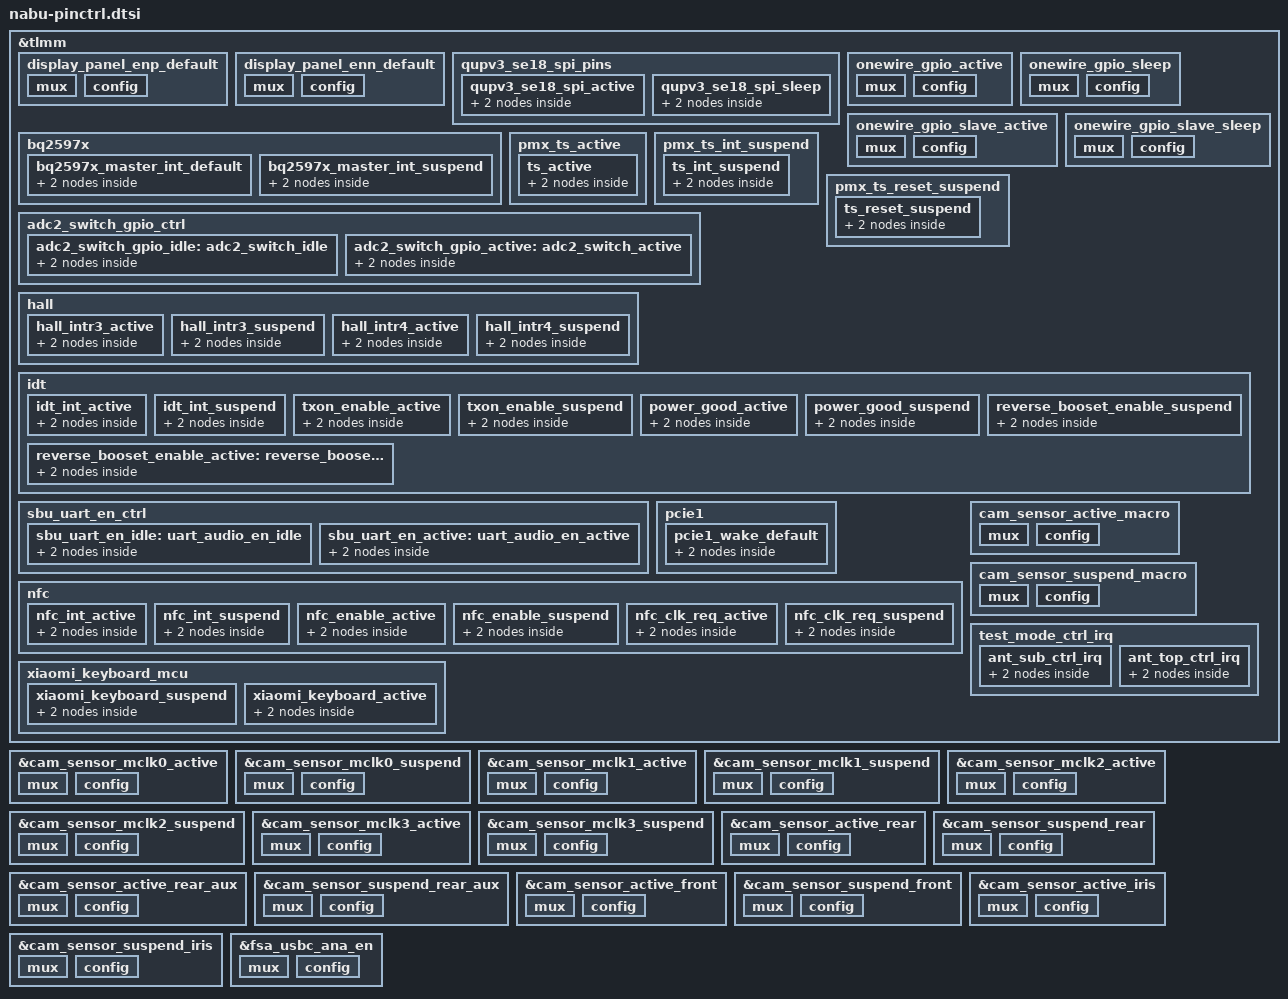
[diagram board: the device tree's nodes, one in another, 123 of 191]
/*for xiaomi pinctrl*/
&tlmm {
	/* display_panel_enp +5V */
	display_panel_enp_default: display_panel_enp_default {
		mux {
			pins = "gpio114";
			function = "gpio";
		};
		config {
			pins = "gpio114";
			drive-strength = <8>;
			bias-disable = <0>;
			output-high;
		};
	};

	/* display_panel_enn -5V */
	display_panel_enn_default: display_panel_enn_default {
		mux {
			pins = "gpio115";
			function = "gpio";
		};
		config {
			pins = "gpio115";
			drive-strength = <8>;
			bias-disable = <0>;
			output-high;
		};
	};

	qupv3_se18_spi_pins: qupv3_se18_spi_pins {
		qupv3_se18_spi_active: qupv3_se18_spi_active {
			mux {
				pins = "gpio23", "gpio24", "gpio25";
				function = "qup18";
			};

			config {
				pins = "gpio23", "gpio24", "gpio25";
				drive-strength = <6>;
				bias-disable;
			};
		};

		qupv3_se18_spi_sleep: qupv3_se18_spi_sleep {
			mux {
				pins = "gpio23", "gpio24", "gpio25";
				function = "gpio";
			};

			config {
				pins = "gpio23", "gpio24", "gpio25";
				drive-strength = <6>;
				bias-disable;
			};
		};
	};


	bq2597x {
		bq2597x_master_int_default: bq2597x_master_int_default {
			/* active state */
			mux {
				/* GPIO 36 is used for bq25970 master ic interrupt usage */
				pins = "gpio36";
				function = "gpio";
			};

			config {
				pins = "gpio36";
				drive-strength = <2>; /* 2 MA */
				bias-pull-up;
				input-enable;
			};
		};

		bq2597x_master_int_suspend: bq2597x_master_int_suspend {
			/* sleep state */
			mux {
				/* GPIO 36 is used for bq25970 master ic interrupt usage */
				pins = "gpio36";
				function = "gpio";
			};

			config {
				pins = "gpio36";
				drive-strength = <2>; /* 2 MA */
				bias-pull-up;
				input-enable;
			};
		};
	};

	onewire_gpio_active: onewire_gpio_active {
		mux {
			pins = "gpio5";
			function = "gpio";
		};

		config {
			pins = "gpio5";
			drive-strength = <2>;
			bias-pull-up; /* No PULL */
		};
	};

	onewire_gpio_sleep: onewire_gpio_sleep {
		mux {
			pins = "gpio5";
			function = "gpio";
		};

		config {
			pins = "gpio5";
			drive-strength = <2>;
			bias-pull-up;
		};
	};

        onewire_gpio_slave_active: onewire_gpio_slave_active {
                mux {
                        pins = "gpio10";
                        function = "gpio";
                };

                config {
                        pins = "gpio10";
                        drive-strength = <2>;
                        bias-pull-up; /* No PULL */
                };
        };

        onewire_gpio_slave_sleep: onewire_gpio_slave_sleep {
                mux {
                        pins = "gpio10";
                        function = "gpio";
                };

                config {
                        pins = "gpio10";
                        drive-strength = <2>;
                        bias-pull-up;
                };
        };

	pmx_ts_active {
		ts_active: ts_active {
				mux {
					pins = "gpio122", "gpio12";
					function = "gpio";
				};
				config {
					pins = "gpio122", "gpio12";
					drive-strength = <8>;
					bias-pull-up;
				};
		};
	};

	pmx_ts_int_suspend {
		ts_int_suspend: ts_int_suspend {
			mux {
				pins = "gpio122";
				function = "gpio";
			};
			config {
				pins = "gpio122";
				drive-strength = <2>;
				bias-pull-down;
				input-enable;
			};
		};
	};

	pmx_ts_reset_suspend {
		ts_reset_suspend: ts_reset_suspend {
			mux {
				pins = "gpio12";
				function = "gpio";
			};
			config {
				pins = "gpio12";
				drive-strength = <2>;
				bias-disable;
				output-low;
			};
		};
	};

	adc2_switch_gpio_ctrl {
		adc2_switch_gpio_idle: adc2_switch_idle {
			mux {
				pins = "gpio142";
				function = "gpio";
			};
			config {
				pins = "gpio142";
				drive-strength = <2>;
				bias-pull-down;
				output-low;
			};
		};

		adc2_switch_gpio_active: adc2_switch_active {
			mux {
				pins = "gpio142";
				function = "gpio";
			};
			config {
				pins = "gpio142";
				drive-strength = <2>;
				bias-disable;
				output-high;
			};
		};
	};

	hall {
		hall_intr3_active: hall_intr3_active {
			/* active state */
			mux {
				pins = "gpio101";
				function = "gpio";
			};

			config {
				pins = "gpio101";
				drive-strength = <2>; /* 2 MA */
				bias-pull-up;
				input-enable;
			};
		};

		hall_intr3_suspend: hall_intr3_suspend {
			/* sleep state */
			mux {
				pins = "gpio101";
				function = "gpio";
			};

			config {
				pins = "gpio101";
				drive-strength = <2>; /* 2 MA */
				bias-pull-up;
				input-enable;
			};
		};

		hall_intr4_active: hall_intr4_active {
			/* active state */
			mux {
				pins = "gpio134";
				function = "gpio";
			};

			config {
				pins = "gpio134";
				drive-strength = <2>; /* 2 MA */
				bias-pull-up;
				input-enable;
			};
		};

		hall_intr4_suspend: hall_intr4_suspend {
			/* sleep state */
			mux {
				pins = "gpio134";
				function = "gpio";
			};

			config {
				pins = "gpio134";
				drive-strength = <2>; /* 2 MA */
				bias-pull-up;
				input-enable;
			};
		};
	};

	idt {
		idt_int_active: idt_int_active {
			/* active state */
			mux {
				pins = "gpio95";
				function = "gpio";
			};

			config {
				pins = "gpio95";
				drive-strength = <2>; /* 2 MA */
				bias-pull-up;
				input-enable;
			};
		};

		idt_int_suspend: idt_int_suspend {
			/* sleep state */
			mux {
				pins = "gpio95";
				function = "gpio";
			};

			config {
				pins = "gpio95";
				drive-strength = <2>; /* 2 MA */
				bias-pull-up;
				input-enable;
			};
		};

		txon_enable_active: txon_enable_active {
			/* active state */
			mux {
				pins = "gpio3";
				function = "gpio";
			};

			config {
				pins = "gpio3";
				drive-strength = <16>;
				bias-disable;
				bias-pull-down;
				output-low;
			};
		};

		txon_enable_suspend: txon_enable_suspend {
			/* sleep state */
			mux {
				pins = "gpio3";
				function = "gpio";
			};

			config {
				pins = "gpio3";
				drive-strength = <16>;
				bias-disable;
				bias-pull-down;
				output-low;
			};
		};

		power_good_active: power_good_active {
			/* active state */
			mux {
				pins = "gpio94";
				function = "gpio";
			};
			config {
				pins = "gpio94";
				drive-strength = <2>; /* 2 MA */
				bias-pull-down;
				input-enable;
				};

		};

		power_good_suspend: power_good_suspend {
			/* active state */
			mux {
				pins = "gpio94";
				function = "gpio";
			};
			config {
				pins = "gpio94";
				drive-strength = <2>; /* 2 MA */
				bias-pull-up;
				input-enable;
				};
		};

		reverse_booset_enable_active: reverse_booset_enable__active {
			/* active state */
			mux {
				pins = "gpio47";
				function = "gpio";
			};

			config {
				pins = "gpio47";
				drive-strength = <16>;
				bias-pull-down;
				output-low;
			};
		};

		reverse_booset_enable_suspend: reverse_booset_enable_suspend {
			/* sleep state */
			mux {
				pins = "gpio47";
				function = "gpio";
			};

			config {
				pins = "gpio47";
				drive-strength = <16>;
				bias-pull-down;
				output-low;
			};
		};
	};

	sbu_uart_en_ctrl {
		sbu_uart_en_idle: uart_audio_en_idle {
			mux {
				pins = "gpio25";
				function = "gpio";
			};
			config {
				pins = "gpio25";
				drive-strength = <2>;
				bias-pull-down;
				output-low;
			};
		};

		sbu_uart_en_active: uart_audio_en_active {
			mux {
				pins = "gpio25";
				function = "gpio";
			};
			config {
				pins = "gpio25";
				drive-strength = <2>;
				bias-disable;
				output-high;
			};
		};
	};


	pcie1 {
		pcie1_wake_default: pcie1_wake_default {
			mux {
				pins = "gpio114";
				function = "gpio";
			};

			config {
				pins = "gpio114";
				drive-strength = <2>;
				bias-pull-up;
			};
		};
	};

	nfc {
		nfc_int_active: nfc_int_active {
			/* active state */
			mux {
				/* GPIO 47 NFC Read Interrupt */
				pins = "gpio47";
				function = "gpio";
			};

			config {
				pins = "gpio47";
				drive-strength = <2>; /* 2 MA */
				bias-pull-up;
			};
		};

		nfc_int_suspend: nfc_int_suspend {
			/* sleep state */
			mux {
				/* GPIO 47 NFC Read Interrupt */
				pins = "gpio47";
				function = "gpio";
			};

			config {
				pins = "gpio47";
				drive-strength = <2>; /* 2 MA */
				bias-pull-up;
			};
		};

		nfc_enable_active: nfc_enable_active {
			/* active state */
			mux {
				/* 41: NFC ENABLE 42:ESE Enable */
				pins = "gpio48", "gpio102";
				function = "gpio";
			};

			config {
				pins = "gpio48", "gpio102";
				drive-strength = <2>; /* 2 MA */
				bias-pull-up;
			};
		};

		nfc_enable_suspend: nfc_enable_suspend {
			/* sleep state */
			mux {
				/* 41: NFC ENABLE 42:ESE Enable */
				pins = "gpio48", "gpio102";
				function = "gpio";
			};

			config {
				pins = "gpio48", "gpio102";
				drive-strength = <2>; /* 2 MA */
				bias-disable;
			};
		};

		nfc_clk_req_active: nfc_clk_req_active {
			/* active state */
			mux {
				/* 113: NFC CLOCK REQUEST */
				pins = "gpio113";
				function = "gpio";
			};

			config {
				pins = "gpio113";
				drive-strength = <2>; /* 2 MA */
				bias-pull-up;
			};
		};

		nfc_clk_req_suspend: nfc_clk_req_suspend {
			/* sleep state */
			mux {
				/* 113: NFC CLOCK REQUEST */
				pins = "gpio113";
				function = "gpio";
			};

			config {
				pins = "gpio113";
				drive-strength = <2>; /* 2 MA */
				bias-disable;
			};
		};
	};
        cam_sensor_active_macro: cam_sensor_active_macro {
                /* RESET macro */
                mux {
                        pins = "gpio27", "gpio94";
                        function = "gpio";
                };

                config {
                        pins = "gpio27", "gpio94";
                        bias-disable; /* No PULL */
                        drive-strength = <2>; /* 2 MA */
                };
        };

        cam_sensor_suspend_macro: cam_sensor_suspend_macro {
                /* RESET MACRO */
                mux {
                        pins = "gpio27", "gpio94";
                        function = "gpio";
                };

                config {
                        pins = "gpio27", "gpio94";
                        bias-pull-down; /* PULL DOWN */
                        drive-strength = <2>; /* 2 MA */
                        output-low;
                };
        };

        test_mode_ctrl_irq {
		ant_sub_ctrl_irq: ant_sub_ctrl_irq {
			mux {
				pins = "gpio81";
				function = "gpio";
			};
			config {
				pins = "gpio81";
				drive-strength = <2>;
				bias-pull-up;
				input-enable;
			};
		};
		ant_top_ctrl_irq: ant_top_ctrl_irq {
			mux {
				pins = "gpio133";
				function = "gpio";
			};
			config {
				pins = "gpio133";
				drive-strength = <2>;
				bias-pull-up;
				input-enable;
			};
		};
	};

	xiaomi_keyboard_mcu {
		xiaomi_keyboard_suspend: xiaomi_keyboard_suspend {
			mux {
				pins = "gpio4";
				function = "gpio";
			};

			config {
				pins = "gpio4";
				drive-strength = <8>;
				bias-pull-down;
			};
		};

		xiaomi_keyboard_active: xiaomi_keyboard_active {
			mux {
				pins = "gpio4";
				function = "gpio";
			};

			config {
				pins = "gpio4";
				drive-strength = <8>;
				bias-pull-up;
			};
		};
	};

};

//camera voltage start
&cam_sensor_mclk0_active {
	/* MCLK0 */
	mux {
		pins = "gpio13";
		function = "cam_mclk";
	};

	config {
		pins = "gpio13";
		bias-disable; /* No PULL */
		drive-strength = <6>; /* 2 MA */
	};
};

&cam_sensor_mclk0_suspend {
	/* MCLK0 */
	mux {
		pins = "gpio13";
		function = "cam_mclk";
	};

	config {
		pins = "gpio13";
		bias-pull-down; /* PULL DOWN */
		drive-strength = <6>; /* 2 MA */
	};
};

&cam_sensor_mclk1_active {
	/* MCLK1 */
	mux {
		pins = "gpio14";
		function = "cam_mclk";
	};

	config {
		pins = "gpio14";
		bias-disable; /* No PULL */
		drive-strength = <4>; /* 2 MA */
	};
};

&cam_sensor_mclk1_suspend {
	/* MCLK1 */
	mux {
		pins = "gpio14";
		function = "cam_mclk";
	};

	config {
		pins = "gpio14";
		bias-pull-down; /* PULL DOWN */
		drive-strength = <4>; /* 2 MA */
	};
};

&cam_sensor_mclk2_active {
	/* MCLK2 */
	mux {
		pins = "gpio15";
		function = "cam_mclk";
	};

	config {
		pins = "gpio15";
		bias-disable; /* No PULL */
		drive-strength = <4>; /* 2 MA */
	};
};

&cam_sensor_mclk2_suspend {
	/* MCLK2 */
	mux {
		pins = "gpio15";
		function = "cam_mclk";
	};

	config {
		pins = "gpio15";
		bias-pull-down; /* PULL DOWN */
		drive-strength = <4>; /* 2 MA */
	};
};

&cam_sensor_mclk3_active {
	/* MCLK3 */
	mux {
		pins = "gpio16";
		function = "cam_mclk";
	};

	config {
		pins = "gpio16";
		bias-disable; /* No PULL */
		drive-strength = <4>; /* 2 MA */
	};
};

&cam_sensor_mclk3_suspend {
	/* MCLK3 */
	mux {
		pins = "gpio16";
		function = "cam_mclk";
	};

	config {
		pins = "gpio16";
		bias-pull-down; /* PULL DOWN */
		drive-strength = <4>; /* 2 MA */
	};
};

&cam_sensor_active_rear {
	/* RESET REAR2 */
	mux {
		pins = "gpio28", "gpio11";
		function = "gpio";
	};

	config {
		pins = "gpio28", "gpio11";
		bias-disable; /* No PULL */
		drive-strength = <2>; /* 2 MA */
	};
};

&cam_sensor_suspend_rear {
	/* RESET REAR2 */
	mux {
		pins = "gpio28", "gpio11";
		function = "gpio";
	};

	config {
		pins = "gpio28", "gpio11";
		bias-pull-down; /* PULL DOWN */
		drive-strength = <2>; /* 2 MA */
		output-low;
	};
};

&cam_sensor_active_rear_aux {
	/* RESET REARAUX, VANA REARAUX */
	mux {
		pins = "gpio23", "gpio94";
		function = "gpio";
	};

	config {
		pins = "gpio23", "gpio94";
		bias-disable; /* No PULL */
		drive-strength = <2>; /* 2 MA */
	};
};

&cam_sensor_suspend_rear_aux {
	/* RESET REARAUX, VANA REARAUX */
	mux {
		pins = "gpio23", "gpio94";
		function = "gpio";
	};

	config {
		pins = "gpio23", "gpio94";
		bias-pull-down; /* PULL DOWN */
		drive-strength = <2>; /* 2 MA */
		output-low;
	};
};

&cam_sensor_active_front {
	/* RESET FRONT, VANA FRONT*/
	mux {
		//pins = "gpio54","gpio132","gpio118";
		pins = "gpio30", "gpio31";
		function = "gpio";
	};

	config {
		//pins = "gpio54","gpio132","gpio118";
		pins = "gpio30", "gpio31";
		bias-disable; /* No PULL */
		drive-strength = <2>; /* 2 MA */
	};
};

&cam_sensor_suspend_front {
	/* RESET FRONT, VANA FRONT*/
	mux {
		//pins = "gpio54","gpio132","gpio118";
		pins = "gpio30", "gpio31";
		function = "gpio";
	};

	config {
		//pins = "gpio54","gpio132","gpio118";
		pins = "gpio30", "gpio31";
		bias-pull-down; /* PULL DOWN */
		drive-strength = <2>; /* 2 MA */
		output-low;
	};
};

&cam_sensor_active_iris {
	/* RESET ULTRA, VANA VDIG ULTRA*/
	mux {
		pins = "gpio28","gpio94";
		function = "gpio";
	};

	config {
		pins = "gpio28","gpio94";
		bias-disable; /* No PULL */
		drive-strength = <2>; /* 2 MA */
	};
};

&cam_sensor_suspend_iris {
	/* RESET ULTRA, VANA VDIG ULTRA*/
	mux {
		pins = "gpio28","gpio94";
		function = "gpio";
	};

	config {
		pins = "gpio28","gpio94";
		bias-pull-down; /* PULL DOWN */
		drive-strength = <2>; /* 2 MA */
		output-low;
	};
};
&cam_sensor_active_macro {
        /* RESET ULTRA, VANA VDIG ULTRA*/
        mux {
                pins = "gpio27","gpio94";
                function = "gpio";
        };

        config {
                pins = "gpio27","gpio94";
                bias-disable; /* No PULL */
                drive-strength = <2>; /* 2 MA */
        };
};

&cam_sensor_suspend_macro {
        /* RESET ULTRA, VANA VDIG ULTRA*/
        mux {
                pins = "gpio27","gpio94";
                function = "gpio";
        };

        config {
                pins = "gpio27","gpio94";
                bias-pull-down; /* PULL DOWN */
                drive-strength = <2>; /* 2 MA */
                output-low;
        };
};


//camera voltage end


&fsa_usbc_ana_en {
	 mux {
		 pins = "gpio84";
		 function = "gpio";
	 };

	 config {
		 pins = "gpio84";
		 drive-strength = <2>;
		 bias-disable;
		 output-low;
	 };
};



